# ATSAMR34J17B register map
Vendor: Microchip Technology; Series: SAMR34; File version: 0
CPU: CM0+ r0p0, little endian, no MPU, VTOR, 2 interrupt priority bits, 29 interrupts
Registers are 32-bit, read-write, reset 0x0 unless marked. A register's access mark holds for its fields unless they carry their own. Offsets are from the block's base; [hi:lo] are bit positions; 'fields as' and 'values as' point back to an identical list.

## SUPC — Supply Controller
Base 0x40001400
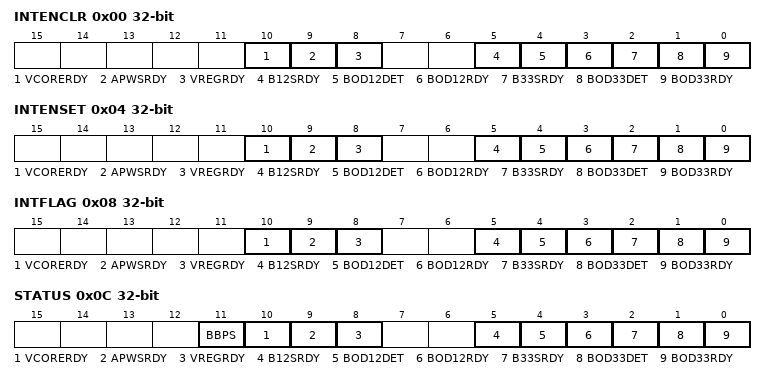
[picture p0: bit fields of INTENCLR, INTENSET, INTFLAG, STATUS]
0x00 INTENCLR write-1-clears — Interrupt Enable Clear
  [10] VCORERDY — VDDCORE Ready
  [9] APWSRDY — Automatic Power Switch Ready
  [8] VREGRDY — Voltage Regulator Ready
  [5] B12SRDY — BOD12 Synchronization Ready
  [4] BOD12DET — BOD12 Detection
  [3] BOD12RDY — BOD12 Ready
  [2] B33SRDY — BOD33 Synchronization Ready
  [1] BOD33DET — BOD33 Detection
  [0] BOD33RDY — BOD33 Ready
0x04 INTENSET write-1-sets — Interrupt Enable Set
  fields as INTENCLR
0x08 INTFLAG write-1-clears — Interrupt Flag Status and Clear
  fields as INTENCLR
0x0C STATUS ro — Power and Clocks Status
  [11] BBPS — Battery Backup Power Switch
  [10] VCORERDY — VDDCORE Ready
  [9] APWSRDY — Automatic Power Switch Ready
  [8] VREGRDY — Voltage Regulator Ready
  [5] B12SRDY — BOD12 Synchronization Ready
  [4] BOD12DET — BOD12 Detection
  [3] BOD12RDY — BOD12 Ready
  [2] B33SRDY — BOD33 Synchronization Ready
  [1] BOD33DET — BOD33 Detection
  [0] BOD33RDY — BOD33 Ready
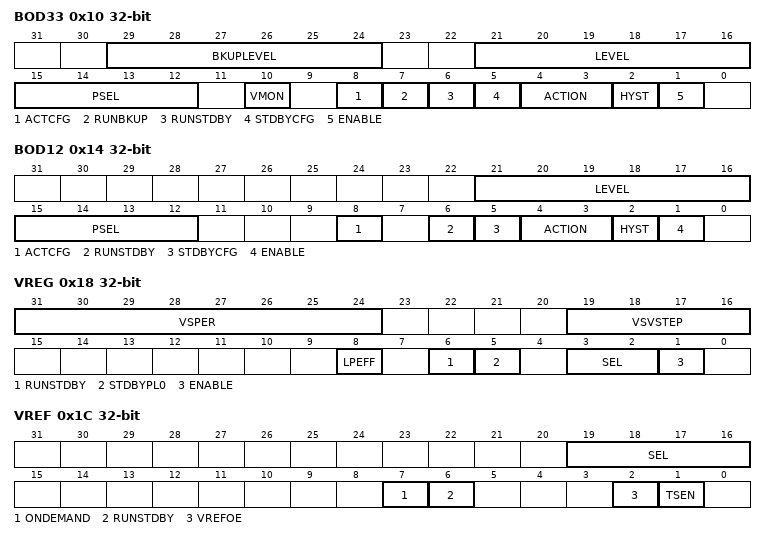
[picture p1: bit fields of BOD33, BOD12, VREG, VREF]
0x10 BOD33 — BOD33 Control
  [29:24] BKUPLEVEL — Threshold Level in backup sleep mode or for VBAT
  [21:16] LEVEL — Threshold Level for VDD
  [15:12] PSEL — Prescaler Select
    0=DIV2 (Divide clock by 2); 1=DIV4 (Divide clock by 4); 2=DIV8 (Divide clock by 8); 3=DIV16 (Divide clock by 16); 4=DIV32 (Divide clock by 32); 5=DIV64 (Divide clock by 64); 6=DIV128 (Divide clock by 128); 7=DIV256 (Divide clock by 256); 8=DIV512 (Divide clock by 512); 9=DIV1024 (Divide clock by 1024); 10=DIV2048 (Divide clock by 2048); 11=DIV4096 (Divide clock by 4096); 12=DIV8192 (Divide clock by 8192); 13=DIV16384 (Divide clock by 16384); 14=DIV32768 (Divide clock by 32768); 15=DIV65536 (Divide clock by 65536)
  [10] VMON — Voltage Monitored in active and standby mode
  [8] ACTCFG — Configuration in Active mode
  [7] RUNBKUP — Configuration in Backup mode
  [6] RUNSTDBY — Run during Standby
  [5] STDBYCFG — Configuration in Standby mode
  [4:3] ACTION — Action when Threshold Crossed
    0=NONE (No action); 1=RESET (The BOD33 generates a reset); 2=INT (The BOD33 generates an interrupt); 3=BKUP (The BOD33 puts the device in backup sleep mode if VMON=0)
  [2] HYST — Hysteresis Enable
  [1] ENABLE
0x14 BOD12 — BOD12 Control
  [21:16] LEVEL — Threshold Level
  [15:12] PSEL — Prescaler Select
    values as BOD33.PSEL
  [8] ACTCFG — Configuration in Active mode
  [6] RUNSTDBY — Run during Standby
  [5] STDBYCFG — Configuration in Standby mode
  [4:3] ACTION — Action when Threshold Crossed
    0=NONE (No action); 1=RESET (The BOD12 generates a reset); 2=INT (The BOD12 generates an interrupt)
  [2] HYST — Hysteresis Enable
  [1] ENABLE
0x18 VREG — VREG Control
  [31:24] VSPER — Voltage Scaling Period
  [19:16] VSVSTEP — Voltage Scaling Voltage Step
  [8] LPEFF — Low Power Efficiency
  [6] RUNSTDBY — Run during Standby
  [5] STDBYPL0 — Standby in PL0
  [3:2] SEL — Voltage Regulator Selection in active mode
    0=LDO (LDO selection); 1=BUCK (Buck selection); 2=SCVREG (Switched Cap selection)
  [1] ENABLE
0x1C VREF — VREF Control
  [19:16] SEL — Voltage Reference Selection
    0=1V0 (1.0V voltage reference typical value); 1=1V1 (1.1V voltage reference typical value); 2=1V2 (1.2V voltage reference typical value); 3=1V25 (1.25V voltage reference typical value); 4=2V0 (2.0V voltage reference typical value); 5=2V2 (2.2V voltage reference typical value); 6=2V4 (2.4V voltage reference typical value); 7=2V5 (2.5V voltage reference typical value)
  [7] ONDEMAND — On Demand Contrl
  [6] RUNSTDBY — Run during Standby
  [2] VREFOE — Voltage Reference Output Enable
  [1] TSEN — Temperature Sensor Output Enable
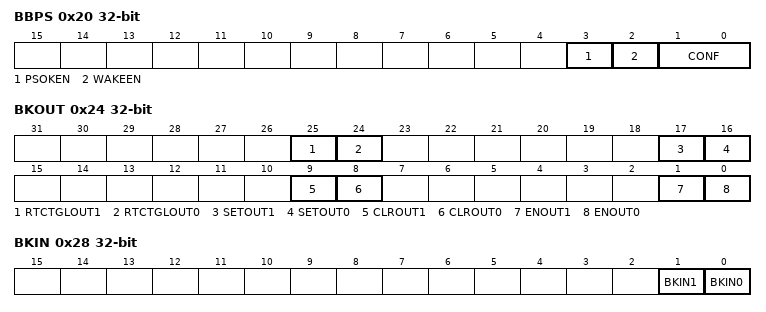
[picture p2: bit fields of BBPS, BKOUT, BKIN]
0x20 BBPS — Battery Backup Power Switch
  [3] PSOKEN — Power Supply OK Enable
  [2] WAKEEN — Wake Enable
  [1:0] CONF — Battery Backup Configuration
    0=NONE (The backup domain is always supplied by main power); 1=APWS (The power switch is handled by the automatic power switch); 2=FORCED (The backup domain is always supplied by battery backup power); 3=BOD33 (The power switch is handled by the BOD33)
0x24 BKOUT — Backup Output Control
  [25] RTCTGLOUT1 — RTC Toggle OUT1
  [24] RTCTGLOUT0 — RTC Toggle OUT0
  [17] SETOUT1
  [16] SETOUT0
  [9] CLROUT1 — Clear OUT1
  [8] CLROUT0 — Clear OUT0
  [1] ENOUT1 — Enable OUT1
  [0] ENOUT0 — Enable OUT0
0x28 BKIN ro — Backup Input Control
  [1] BKIN1 — Backup Input 1
  [0] BKIN0 — Backup Input 0

## Notices in the file
Copyright (c) 2026 Microchip Technology Inc.
SPDX-License-Identifier: Apache-2.0
Licensed under the Apache License, Version 2.0 (the "License");
you may not use this file except in compliance with the License.
You may obtain a copy of the License at
http://www.apache.org/licenses/LICENSE-2.0
Unless required by applicable law or agreed to in writing, software
distributed under the License is distributed on an "AS IS" BASIS,
WITHOUT WARRANTIES OR CONDITIONS OF ANY KIND, either express or implied.
See the License for the specific language governing permissions and
limitations under the License.
